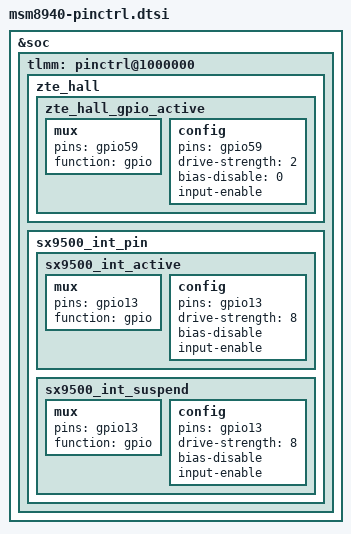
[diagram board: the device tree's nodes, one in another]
/*
 * Copyright (c) 2016, The Linux Foundation. All rights reserved.
 *
 * This program is free software; you can redistribute it and/or modify
 * it under the terms of the GNU General Public License version 2 and
 * only version 2 as published by the Free Software Foundation.
 *
 * This program is distributed in the hope that it will be useful,
 * but WITHOUT ANY WARRANTY; without even the implied warranty of
 * MERCHANTABILITY or FITNESS FOR A PARTICULAR PURPOSE.  See the
 * GNU General Public License for more details.
 */

#include "msm8937-pinctrl.dtsi"

&soc {
	tlmm: pinctrl@1000000 {
		zte_hall: zte_hall {
			zte_hall_gpio_active: zte_hall_gpio_active {
				mux {
					pins = "gpio59";
					function = "gpio";
				};
				config {
					pins = "gpio59";
					drive-strength = <2>; /* 2 mA */
					bias-disable = <0>; /* no pull */
					input-enable; /* input */
				};
			};
		};

		sx9500_int_pin {
			sx9500_int_active: sx9500_int_active {
				mux {
					pins = "gpio13";
					function = "gpio";
				};
				config {
					pins = "gpio13";
					drive-strength = <8>;
					bias-disable;
					input-enable;
				};
			};
			sx9500_int_suspend: sx9500_int_suspend {
				mux {
					pins = "gpio13";
					function = "gpio";
				};
				config {
					pins = "gpio13";
					drive-strength = <8>;
					bias-disable;
					input-enable;
				};
			};
		};
	};
};
